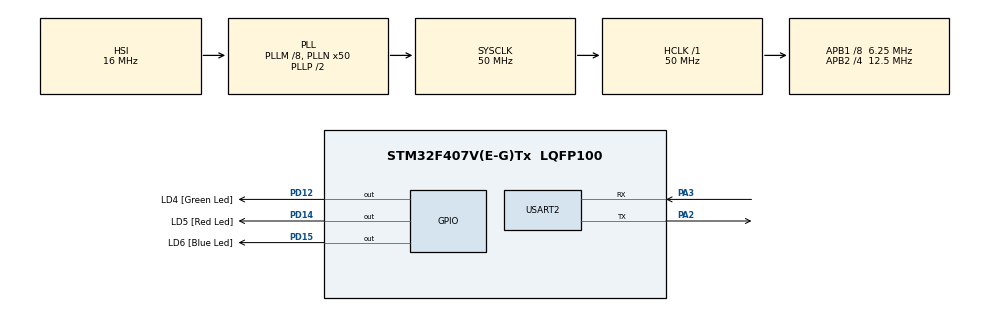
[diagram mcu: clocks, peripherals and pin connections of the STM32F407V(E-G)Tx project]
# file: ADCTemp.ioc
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Mcu.Family=STM32F4
PD12.GPIO_Label=LD4 [Green Led]
RCC.CortexFreq_Value=50000000
PD12.GPIO_Speed=GPIO_SPEED_FREQ_LOW
ADC1.Rank-0\#ChannelRegularConversion=1
PD15.GPIO_Label=LD6 [Blue Led]
VP_ADC1_TempSens_Input.Mode=IN-TempSens
ADC1.ContinuousConvMode=ENABLE
PD15.GPIO_Speed=GPIO_SPEED_FREQ_LOW
RCC.APB1CLKDivider=RCC_HCLK_DIV8
RCC.SYSCLKSource=RCC_SYSCLKSOURCE_PLLCLK
ProjectManager.StackSize=0x400
PA3.Mode=Asynchronous
NVIC.ADC_IRQn=true\:0\:0\:false\:false\:true\:true\:true
PD14.GPIO_Speed=GPIO_SPEED_FREQ_LOW
ProjectManager.TargetToolchain=STM32CubeIDE
RCC.HCLKFreq_Value=50000000
RCC.APB2TimFreq_Value=25000000
RCC.LSE_VALUE=32768
RCC.AHBFreq_Value=50000000
ADC1.Channel-0\#ChannelRegularConversion=ADC_CHANNEL_TEMPSENSOR
RCC.HSE_VALUE=8000000
board=STM32F407G-DISC1
RCC.VCOOutputFreq_Value=100000000
RCC.APB2Freq_Value=12500000
PD14.GPIO_PuPd=GPIO_NOPULL
PD14.GPIO_Label=LD5 [Red Led]
Mcu.Name=STM32F407V(E-G)Tx
ADC1.SamplingTime-0\#ChannelRegularConversion=ADC_SAMPLETIME_480CYCLES
PA2.Signal=USART2_TX
PD14.Signal=GPIO_Output
RCC.48MHZClocksFreq_Value=14285714.285714285
RCC.SYSCLKFreq_VALUE=50000000
Mcu.Package=LQFP100
ADC1.master=1
USART2.VirtualMode=VM_ASYNC
PD12.Signal=GPIO_Output
PD15.GPIO_PuPd=GPIO_NOPULL
ProjectManager.HeapSize=0x200
RCC.HSI_VALUE=16000000
RCC.PLLQ=7
NVIC.PriorityGroup=NVIC_PRIORITYGROUP_0
ADC1.NbrOfConversionFlag=1
RCC.APB2CLKDivider=RCC_HCLK_DIV4
RCC.PLLM=8
RCC.PLLN=50
RCC.APB1TimFreq_Value=12500000
PA2.Mode=Asynchronous
RCC.APB1Freq_Value=6250000
ADC1.ClockPrescaler=ADC_CLOCK_SYNC_PCLK_DIV4
ADC1.EOCSelection=ADC_EOC_SEQ_CONV
PD15.Signal=GPIO_Output
PD12.GPIO_PuPd=GPIO_NOPULL
PA3.Signal=USART2_RX

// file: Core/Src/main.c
/* USER CODE BEGIN Header */
/* @file         : main.c */
/* USER CODE END Header */
#include "main.h"
/* USER CODE BEGIN Includes */
#include "string.h"
#include "stdio.h"
#include "retarget.h"
/* USER CODE END Includes */

ADC_HandleTypeDef hadc1;
UART_HandleTypeDef huart2;

void SystemClock_Config(void);
static void MX_GPIO_Init(void);
static void MX_ADC1_Init(void);
static void MX_USART2_UART_Init(void);

int main(void)
{

  /* MCU Configuration--------------------------------------------------------*/
  /* Reset of all peripherals, Initializes the Flash interface and the Systick. */
  HAL_Init();

  /* Configure the system clock */
  SystemClock_Config();

  /* Initialize all configured peripherals */
  MX_GPIO_Init();
  MX_ADC1_Init();
  MX_USART2_UART_Init();
  /* USER CODE BEGIN 2 */
  HAL_NVIC_SetPriority(ADC_IRQn, 0, 0);
  HAL_NVIC_EnableIRQ(ADC_IRQn);
  HAL_ADC_Start_IT(&hadc1);
  RetargetInit(&huart2);
  /* indirizzi di memoria dei registri di DWT */
  volatile uint32_t *DWT_CONTROL = (uint32_t*) 0xE0001000;
  volatile uint32_t *DWT_CYCCNT = (uint32_t*) 0xE0001004;
  /* Reset e abilitazione del registro counter */
  *DWT_CYCCNT = 0;
  *DWT_CONTROL |= 0x1;
  /* USER CODE END 2 */

  while (1)
  {
  }
}

void SystemClock_Config(void)
{
  RCC_OscInitTypeDef RCC_OscInitStruct = {0};
  RCC_ClkInitTypeDef RCC_ClkInitStruct = {0};

  /** Configure the main internal regulator output voltage
  */
  __HAL_RCC_PWR_CLK_ENABLE();
  __HAL_PWR_VOLTAGESCALING_CONFIG(PWR_REGULATOR_VOLTAGE_SCALE1);
  /** Initializes the RCC Oscillators according to the specified parameters
  * in the RCC_OscInitTypeDef structure.
  */
  RCC_OscInitStruct.OscillatorType = RCC_OSCILLATORTYPE_HSI;
  RCC_OscInitStruct.HSIState = RCC_HSI_ON;
  RCC_OscInitStruct.HSICalibrationValue = RCC_HSICALIBRATION_DEFAULT;
  RCC_OscInitStruct.PLL.PLLState = RCC_PLL_ON;
  RCC_OscInitStruct.PLL.PLLSource = RCC_PLLSOURCE_HSI;
  RCC_OscInitStruct.PLL.PLLM = 8;
  RCC_OscInitStruct.PLL.PLLN = 50;
  RCC_OscInitStruct.PLL.PLLP = RCC_PLLP_DIV2;
  RCC_OscInitStruct.PLL.PLLQ = 7;
  if (HAL_RCC_OscConfig(&RCC_OscInitStruct) != HAL_OK)
  {
    Error_Handler();
  }
  /** Initializes the CPU, AHB and APB buses clocks
  */
  RCC_ClkInitStruct.ClockType = RCC_CLOCKTYPE_HCLK|RCC_CLOCKTYPE_SYSCLK
                              |RCC_CLOCKTYPE_PCLK1|RCC_CLOCKTYPE_PCLK2;
  RCC_ClkInitStruct.SYSCLKSource = RCC_SYSCLKSOURCE_PLLCLK;
  RCC_ClkInitStruct.AHBCLKDivider = RCC_SYSCLK_DIV1;
  RCC_ClkInitStruct.APB1CLKDivider = RCC_HCLK_DIV8;
  RCC_ClkInitStruct.APB2CLKDivider = RCC_HCLK_DIV4;

  if (HAL_RCC_ClockConfig(&RCC_ClkInitStruct, FLASH_LATENCY_1) != HAL_OK)
  {
    Error_Handler();
  }
}

static void MX_ADC1_Init(void)
{
  ADC_ChannelConfTypeDef sConfig = {0};

  /** Configure the global features of the ADC (Clock, Resolution, Data Alignment and number of conversion)
  */
  hadc1.Instance = ADC1;
  hadc1.Init.ClockPrescaler = ADC_CLOCK_SYNC_PCLK_DIV4;
  hadc1.Init.Resolution = ADC_RESOLUTION_12B;
  hadc1.Init.ScanConvMode = DISABLE;
  hadc1.Init.ContinuousConvMode = ENABLE;
  hadc1.Init.DiscontinuousConvMode = DISABLE;
  hadc1.Init.ExternalTrigConvEdge = ADC_EXTERNALTRIGCONVEDGE_NONE;
  hadc1.Init.ExternalTrigConv = ADC_SOFTWARE_START;
  hadc1.Init.DataAlign = ADC_DATAALIGN_RIGHT;
  hadc1.Init.NbrOfConversion = 1;
  hadc1.Init.DMAContinuousRequests = DISABLE;
  hadc1.Init.EOCSelection = ADC_EOC_SEQ_CONV;
  if (HAL_ADC_Init(&hadc1) != HAL_OK)
  {
    Error_Handler();
  }
  /** Configure for the selected ADC regular channel its corresponding rank in the sequencer and its sample time.
  */
  sConfig.Channel = ADC_CHANNEL_TEMPSENSOR;
  sConfig.Rank = 1;
  sConfig.SamplingTime = ADC_SAMPLETIME_480CYCLES;
  if (HAL_ADC_ConfigChannel(&hadc1, &sConfig) != HAL_OK)
  {
    Error_Handler();
  }
}

static void MX_USART2_UART_Init(void)
{

  huart2.Instance = USART2;
  huart2.Init.BaudRate = 115200;
  huart2.Init.WordLength = UART_WORDLENGTH_8B;
  huart2.Init.StopBits = UART_STOPBITS_1;
  huart2.Init.Parity = UART_PARITY_NONE;
  huart2.Init.Mode = UART_MODE_TX_RX;
  huart2.Init.HwFlowCtl = UART_HWCONTROL_NONE;
  huart2.Init.OverSampling = UART_OVERSAMPLING_16;
  if (HAL_UART_Init(&huart2) != HAL_OK)
  {
    Error_Handler();
  }

}

static void MX_GPIO_Init(void)
{
  GPIO_InitTypeDef GPIO_InitStruct = {0};

  /* GPIO Ports Clock Enable */
  __HAL_RCC_GPIOA_CLK_ENABLE();
  __HAL_RCC_GPIOD_CLK_ENABLE();

  /*Configure GPIO pin Output Level */
  HAL_GPIO_WritePin(GPIOD, LD4_Pin|LD5_Pin|LD6_Pin, GPIO_PIN_RESET);

  /*Configure GPIO pins : LD4_Pin LD5_Pin LD6_Pin */
  GPIO_InitStruct.Pin = LD4_Pin|LD5_Pin|LD6_Pin;
  GPIO_InitStruct.Mode = GPIO_MODE_OUTPUT_PP;
  GPIO_InitStruct.Pull = GPIO_NOPULL;
  GPIO_InitStruct.Speed = GPIO_SPEED_FREQ_LOW;
  HAL_GPIO_Init(GPIOD, &GPIO_InitStruct);

}

void HAL_ADC_ConvCpltCallback(ADC_HandleTypeDef* hadc) {
	char msg[30];
	uint16_t rawValue;
	float temp;	// temperatura
	/* Ottengo il dato, poi da convertire in gradi celsius */
	rawValue = HAL_ADC_GetValue(&hadc1);
	temp = ((float)rawValue) / 4095 * 2900;	//2900 è il VDD misurato sulla board, anzichè 3.3V
	temp = ((temp - 760.0) / 2.5) + 25;
	/* Stampo via UART il dato acquisito da ADC */
	sprintf(msg, "Raw Value = %hu\r\n", rawValue);
	HAL_UART_Transmit(&huart2, (uint8_t*) msg, strlen(msg), HAL_MAX_DELAY);
	/* Stampo via UART la temperatura convertita */
	sprintf(msg, "Temperature = %.2f Celsius\r\n", temp);
	HAL_UART_Transmit(&huart2, (uint8_t*) msg, strlen(msg), HAL_MAX_DELAY);
	// LEDS
	HAL_GPIO_WritePin(GPIOD, GPIO_PIN_12|GPIO_PIN_14|GPIO_PIN_15, 0);
	/* temperatura troppo calda: led rosso */
	if(temp>28)
	{
		HAL_GPIO_WritePin(GPIOD, GPIO_PIN_14, 1);
	}
	/* temperatura troppo fredda: led blu */
	else if(temp<18)
	{
		HAL_GPIO_WritePin(GPIOD, GPIO_PIN_15, 1);
	}
	/* temperatura regolare: led verde */
	else
	{
		HAL_GPIO_WritePin(GPIOD, GPIO_PIN_12, 1);
	}
	/* delay di attesa per rallentare l'output */
	for(int i = 0; i < 0xfffff; i++);
}

void Error_Handler(void)
{
  __disable_irq();
  while (1)
  {
  }
}
